# RZN2H register map
Vendor: Renesas Electronics Corporation; Series: RZN; File version: 1.00.00
CPU: other r0p0, little endian, MPU, no FPU, VTOR, 4 interrupt priority bits, 624 interrupts
Registers are 32-bit, read-write, reset 0x0 unless marked. A register's access mark holds for its fields unless they carry their own. Offsets are from the block's base; [hi:lo] are bit positions; {n}, {i} and the like mark numbered series; 'fields as' and 'values as' point back to an identical list.

## SYSC_S — Register Write Protection for Safety Area
Base 0x81280000
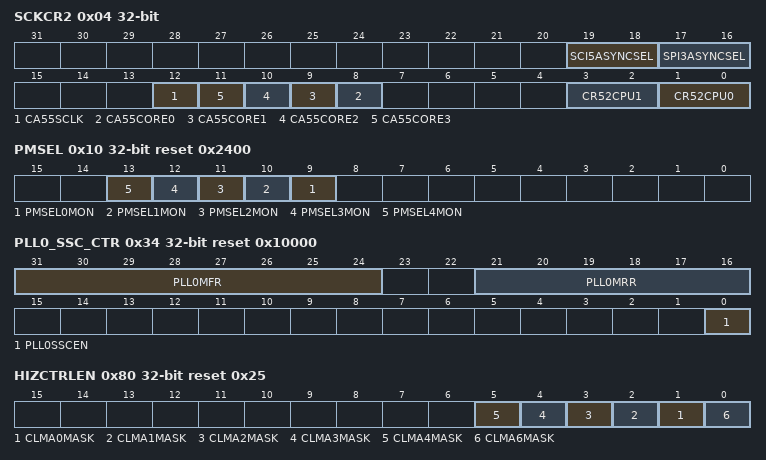
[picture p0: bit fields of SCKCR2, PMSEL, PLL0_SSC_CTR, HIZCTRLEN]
0x04 SCKCR2 — System Clock Control Register 2
  [19:18] SCI5ASYNCSEL
    0=75.0 MHz; 1=80.0 MHz; 2=96.0 MHz; 3=100.0 MHz
  [17:16] SPI3ASYNCSEL
    0=75.0 MHz; 1=80.0 MHz; 2=96.0 MHz; 3=100.0 MHz
  [12] CA55SCLK
    0=500.0 MHz; 1=1000.0 MHz
  [n+8] CA55CORE{n} (n=0..3)
    0=600.0 MHz; 1=1200.0 MHz
  [3:2] CR52CPU1
    0=500.0 MHz; 1=1000.0 MHz; 2=Setting prohibited; 3=Setting prohibited
  [1:0] CR52CPU0
    values as CR52CPU1
0x10 PMSEL reset 0x2400 — PLL/Main OSC clock Select Register
  [n+9] PMSEL{n}MON ro (n=0..4)
    0=External clock; 1=PLL{n} output clock
0x20 PLL0MON ro — PLL0 Monitor Register
  [0] PLL0MON — PLL0 Lock State Monitor
    0=PLL0 is not locked; 1=PLL0 is locked
0x30 PLL0EN — PLL0 Enable Register
  [0] PLL0EN
    0=PLL0 is in standby state; 1=PLL0 is released from standby state
0x34 PLL0_SSC_CTR reset 0x10000 — PLL0 SSC Control Register
  [31:24] PLL0MFR
  [21:16] PLL0MRR
  [0] PLL0SSCEN
    0=SSC is disabled; 1=SSC is enabled
0x40 PLL1MON ro reset 0x1 — PLL1 Monitor Register
  [0] PLL1MON — PLL1 Lock State Monitor
    0=PLL1 is not locked; 1=PLL1 is locked
0x70 LOCOCR — Low-Speed On-Chip Oscillator Control Register
  [0] LCSTP — LOCO Stop
    0=Stop; 1=Run
0x80 HIZCTRLEN reset 0x25 — High-Impedance Control Enable Register
  [n+1] CLMA{n}MASK (n=0..4)
    0=CLMA{n} error is not transferred to POE3 and POEG; 1=CLMA{n} error is transferred to POE3 and POEG
  [0] CLMA6MASK
    0=CLMA6 error is not transferred to POE3 and POEG; 1=CLMA6 error is transferred to POE3 and POEG
0x90 PLL2MON ro — PLL2 Monitor Register
  [0] PLL2MON — PLL2 Lock State Monitor
    0=PLL2 is not locked; 1=PLL2 is locked
0xA0 PLL2EN — PLL2 Enable Register
  [0] PLL2EN
    0=PLL2 is in standby state; 1=PLL2 is released from standby state
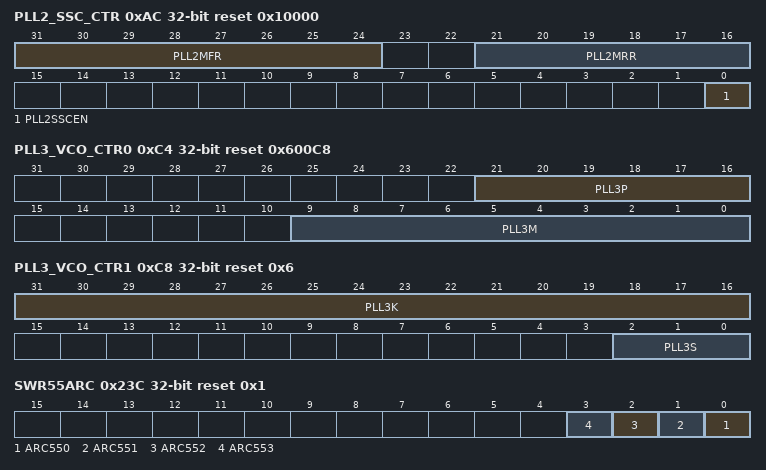
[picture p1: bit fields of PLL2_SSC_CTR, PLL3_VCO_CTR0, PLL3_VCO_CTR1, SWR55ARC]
0xAC PLL2_SSC_CTR reset 0x10000 — PLL2 SSC Control Register
  [31:24] PLL2MFR
  [21:16] PLL2MRR
  [0] PLL2SSCEN
    0=SSC is disabled; 1=SSC is enabled
0xB0 PLL3MON ro — PLL3 Monitor Register
  [0] PLL3MON — PLL3 Lock State Monitor
    0=PLL3 is not locked; 1=PLL3 is locked
0xC0 PLL3EN — PLL3 Enable Register
  [0] PLL3EN
    0=PLL3 is in standby state; 1=PLL3 is released from standby state
0xC4 PLL3_VCO_CTR0 reset 0x600C8 — PLL3 VCO Control Register 0
  [21:16] PLL3P — PLL3 P-Divider Setting
  [9:0] PLL3M — PLL3 M-Divider Setting
0xC8 PLL3_VCO_CTR1 reset 0x6 — PLL3 VCO Control Register 1
  [31:16] PLL3K — PLL3 Delta-Sigma Modulator Setting
  [2:0] PLL3S — PLL3 S-Divider Setting
0xD0 PLL4MON ro reset 0x1 — PLL4 Monitor Register
  [0] PLL4MON — PLL4 Lock State Monitor
    0=PLL4 is not locked; 1=PLL4 is locked
0x210 SWRSYS wo — System Software Reset Register
  [31:0] SWR — System Software Reset
0x220 SWRCPU0 — Cortex-R52 CPU0 Software Reset Register
  [31:0] SWR — Cortex-R52 CPU0 Software Reset
0x224 SWRCPU1 reset 0x1 — Cortex-R52 CPU1 Software Reset Register
  [31:0] SWR — Cortex-R52 CPU1 Software Reset
0x228 SWR55C reset 0x1 — Cortex-A55 Cluster Software Reset Register
  [31:0] SWR — Cortex-A55 Cluster Software Reset
0x22C SWR550 reset 0x1 — Cortex-A55 Core0 Software Reset Register
  [31:0] SWR — Cortex-A55 Core0 Software Reset
0x230 SWR551 reset 0x1 — Cortex-A55 Core1 Software Reset Register
  [31:0] SWR — Cortex-A55 Core1 Software Reset
0x234 SWR552 reset 0x1 — Cortex-A55 Core2 Software Reset Register
  [31:0] SWR — Cortex-A55 Core2 Software Reset
0x238 SWR553 reset 0x1 — Cortex-A55 Core3 Software Reset Register
  [31:0] SWR — Cortex-A55 Core3 Software Reset
0x23C SWR55ARC reset 0x1 — Cortex-A55 Software Reset Automatic Release Control Register
  [all] fields
    0=Reset is not released; 1=Reset is released automatically
  [n-550] ARC{n} (n=550..553)
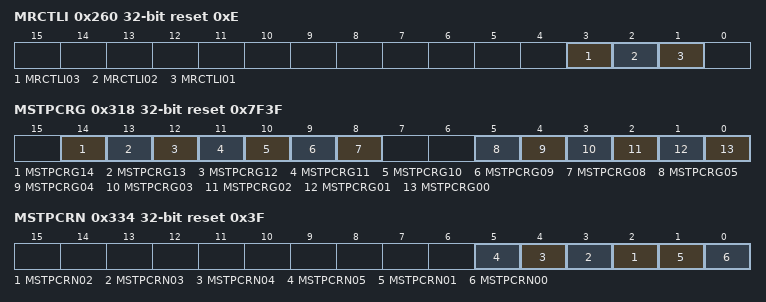
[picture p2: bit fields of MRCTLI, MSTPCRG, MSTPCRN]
0x260 MRCTLI reset 0xE — Module Reset Control Register I
  [3] MRCTLI03 — SHOSTIF (IP clock domain) Reset Control
    0=SHOSTIF (IP clock domain) is released from reset; 1=SHOSTIF (IP clock domain) is in the reset state
  [2] MRCTLI02 — SHOSTIF (Slave bus clock domain) Reset Control
    0=SHOSTIF (Slave bus clock domain) is released from reset; 1=SHOSTIF (Slave bus clock domain) is in the reset state
  [1] MRCTLI01 — SHOSTIF (Master bus clock domain) Reset Control
    0=SHOSTIF (Master bus clock domain) is released from reset; 1=SHOSTIF (Master bus clock domain) is in the reset state
0x318 MSTPCRG reset 0x7F3F — Module Stop Control Register G
  [all] fields
    0=Release from the module-stop state; 1=Transition to the module-stop state is made
  [14] MSTPCRG14
  [13] MSTPCRG13
  [12] MSTPCRG12
  [11] MSTPCRG11 — CLMA2 Module Stop
  [10] MSTPCRG10 — CLMA1 Module Stop
  [9] MSTPCRG09 — CLMA0 Module Stop
  [8] MSTPCRG08 — CLMA6 Module Stop
  [5] MSTPCRG05 — RTC Module Stop
  [4] MSTPCRG04 — CRC Unit 1 Module Stop
  [3] MSTPCRG03 — GPT Unit 10 Module Stop
  [2] MSTPCRG02 — SPI Unit 3 Module Stop
  [1] MSTPCRG01 — IIC Unit 2 Module Stop
  [0] MSTPCRG00 — SCI Unit 5 Module Stop
0x320 MSTPCRI reset 0x2 — Module Stop Control Register I
  [1] MSTPCRI01
    values as the fields of MSTPCRG
0x334 MSTPCRN reset 0x3F — Module Stop Control Register N
  [all] fields
    values as the fields of MSTPCRG
  [n] MSTPCRN{n:02} (n=2..5) — Cortex-A55 Core{n-2} Module Stop
  [1] MSTPCRN01 — Cortex-R52 CPU1 Module Stop
  [0] MSTPCRN00 — Cortex-R52 CPU0 Module Stop
